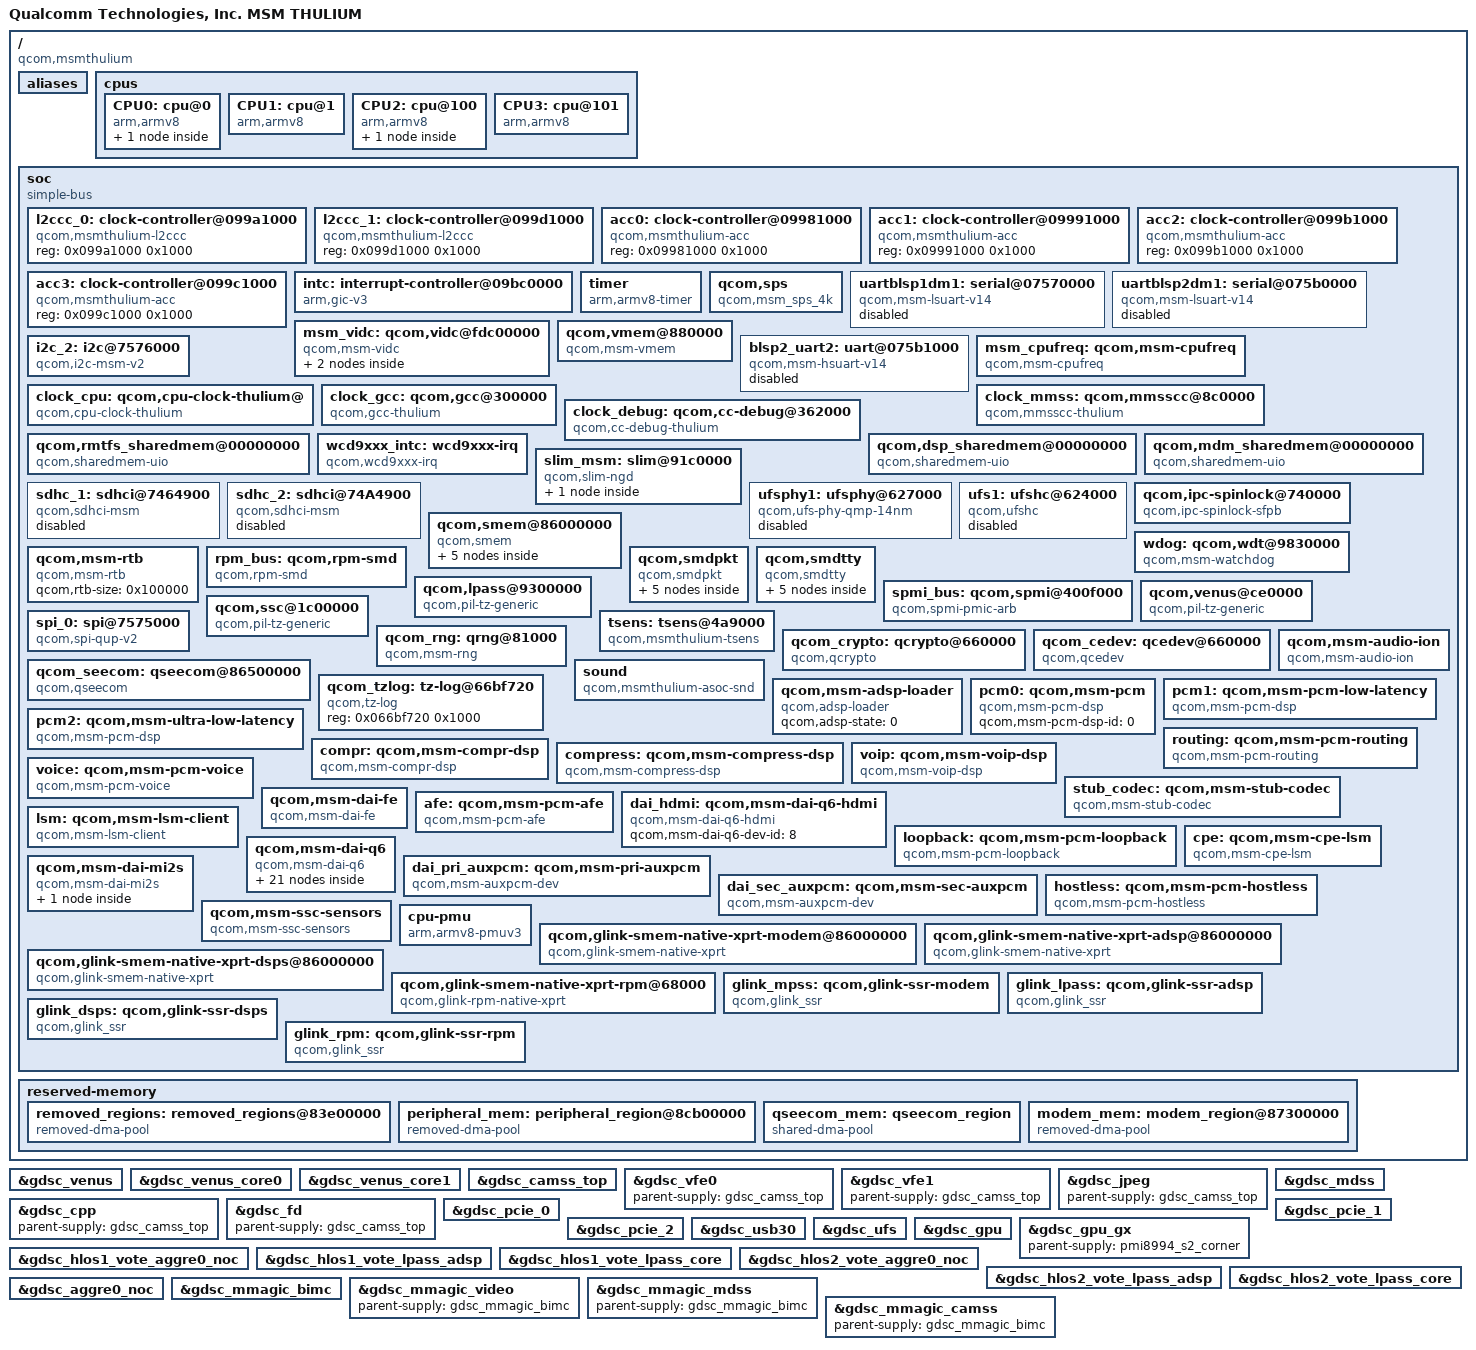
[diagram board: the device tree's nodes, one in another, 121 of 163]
/* Copyright (c) 2014-2015, The Linux Foundation. All rights reserved.
 *
 * This program is free software; you can redistribute it and/or modify
 * it under the terms of the GNU General Public License version 2 and
 * only version 2 as published by the Free Software Foundation.
 *
 * This program is distributed in the hope that it will be useful,
 * but WITHOUT ANY WARRANTY; without even the implied warranty of
 * MERCHANTABILITY or FITNESS FOR A PARTICULAR PURPOSE.  See the
 * GNU General Public License for more details.
 */

#include "skeleton64.dtsi"
#include <dt-bindings/clock/msm-clocks-thulium.h>

/ {
	model = "Qualcomm Technologies, Inc. MSM THULIUM";
	compatible = "qcom,msmthulium";
	qcom,msm-id = <246 0x0>;
	interrupt-parent = <&intc>;

	aliases {
		sdhc1 = &sdhc_1; /* SDC1 eMMC slot */
		sdhc2 = &sdhc_2; /* SDC2 SD card slot */
		smd7 = &smdtty_data1;
		smd8 = &smdtty_data4;
		smd11 = &smdtty_data11;
		smd21 = &smdtty_data21;
		smd36 = &smdtty_loopback;
		i2c2 = &i2c_2;
		spi0 = &spi_0;
	};

	cpus {
		#address-cells = <2>;
		#size-cells = <0>;

		CPU0: cpu@0 {
			device_type = "cpu";
			compatible = "arm,armv8";
			reg = <0x0 0x0>;
			enable-method = "qcom,msmthulium-acc";
			qcom,acc = <&acc0>;
			next-level-cache = <&L2_0>;
			L2_0: l2-cache {
			      compatible = "arm,arch-cache";
			      cache-level = <2>;
			      power-domain = <&l2ccc_0>;
			};

		};

		CPU1: cpu@1 {
			device_type = "cpu";
			compatible = "arm,armv8";
			reg = <0x0 0x1>;
			enable-method = "qcom,msmthulium-acc";
			qcom,acc = <&acc1>;
			next-level-cache = <&L2_0>;
		};

		CPU2: cpu@100 {
			device_type = "cpu";
			compatible = "arm,armv8";
			reg = <0x0 0x100>;
			enable-method = "qcom,msmthulium-acc";
			qcom,acc = <&acc2>;
			next-level-cache = <&L2_1>;
			L2_1: l2-cache {
			      compatible = "arm,arch-cache";
			      cache-level = <2>;
			      power-domain = <&l2ccc_1>;
			};
		};

		CPU3: cpu@101 {
			device_type = "cpu";
			compatible = "arm,armv8";
			reg = <0x0 0x101>;
			enable-method = "qcom,msmthulium-acc";
			qcom,acc = <&acc3>;
			next-level-cache = <&L2_1>;
		};

	};

	soc: soc { };

	reserved-memory {
		#address-cells = <2>;
		#size-cells = <2>;
		ranges;

		removed_regions: removed_regions@83e00000 {
			compatible = "removed-dma-pool";
			no-map;
			reg = <0 0x83e00000 0 0x3500000>;
		};

		peripheral_mem: peripheral_region@8cb00000 {
			compatible = "removed-dma-pool";
			no-map;
			reg = <0 0x8cb00000 0 0x2100000>;
		};

		qseecom_mem: qseecom_region {
			compatible = "shared-dma-pool";
			reusable;
			alignment = <0 0x400000>;
			size = <0 0x1400000>;
		};

		modem_mem: modem_region@87300000 {
			compatible = "removed-dma-pool";
			no-map;
			reg = <0 0x87300000 0 0x5800000>;
		};
	};
};

#include "msmthulium-ion.dtsi"
#include "msmthulium-mdss.dtsi"
#include "msmthulium-smp2p.dtsi"
#include "msmthulium-ipcrouter.dtsi"
#include "msmthulium-iommu.dtsi"
#include "msm-gdsc-thulium.dtsi"
#include "msmthulium-bus.dtsi"
#include "msmthulium-coresight.dtsi"

&soc {
	#address-cells = <1>;
	#size-cells = <1>;
	ranges = <0 0 0 0xffffffff>;
	compatible = "simple-bus";

	l2ccc_0: clock-controller@099a1000 {
		compatible = "qcom,msmthulium-l2ccc";
		reg = <0x099a1000 0x1000>;
	};

	l2ccc_1: clock-controller@099d1000 {
		compatible = "qcom,msmthulium-l2ccc";
		reg = <0x099d1000 0x1000>;
	};

	acc0: clock-controller@09981000 {
		compatible = "qcom,msmthulium-acc";
		reg = <0x09981000 0x1000>;
	};

	acc1: clock-controller@09991000 {
		compatible = "qcom,msmthulium-acc";
		reg = <0x09991000 0x1000>;
	};

	acc2: clock-controller@099b1000 {
		compatible = "qcom,msmthulium-acc";
		reg = <0x099b1000 0x1000>;
	};

	acc3: clock-controller@099c1000 {
		compatible = "qcom,msmthulium-acc";
		reg = <0x099c1000 0x1000>;
	};

	intc: interrupt-controller@09bc0000 {
		compatible = "arm,gic-v3";
		#interrupt-cells = <3>;
		interrupt-controller;
		#redistributor-regions = <1>;
		redistributor-stride = <0x0 0x40000>;
		reg = <0x09bc0000 0x10000>,       /* GICD */
		      <0x09c00000 0x100000>;      /* GICR * 4 */
		interrupts = <1 9 4>;
	};

	timer {
		compatible = "arm,armv8-timer";
		interrupts = <1 13 0xf08>,
			     <1 14 0xf08>,
			     <1 11 0xf08>,
			     <1 10 0xf08>;
		clock-frequency = <19200000>;
	};

	qcom,sps {
		compatible = "qcom,msm_sps_4k";
		qcom,device-type = <3>;
		qcom,pipe-attr-ee;
	};

	uartblsp1dm1: serial@07570000 {
		compatible = "qcom,msm-lsuart-v14";
		reg = <0x7570000 0x1000>;
		interrupts = <0 108 0>;
		status = "disabled";
		clocks = <&clock_gcc clk_gcc_blsp1_uart2_apps_clk>,
			 <&clock_gcc clk_gcc_blsp1_ahb_clk>;
		clock-names = "core_clk", "iface_clk";
	};

	uartblsp2dm1: serial@075b0000 {
		compatible = "qcom,msm-lsuart-v14";
		reg = <0x75b0000 0x1000>;
		interrupts = <0 114 0>;
		status = "disabled";
		clocks = <&clock_gcc clk_gcc_blsp2_uart2_apps_clk>,
			 <&clock_gcc clk_gcc_blsp2_ahb_clk>;
		clock-names = "core_clk", "iface_clk";
	};

	msm_vidc: qcom,vidc@fdc00000 {
		compatible = "qcom,msm-vidc";
		status = "ok";
		reg = <0xC00000 0xff000>;
		interrupts = <0 287 0>;
		qcom,hfi = "venus";
		qcom,max-hw-load = <1281600>; /* Full 4k @ 30 + 1080p @ 30 */
		qcom,imem-size = <1048576>; /* 1 MB */
		qcom,load-freq-tbl =
			/* Encoders */
			<972000 450000000 0x55555555>, /* 4k UHD @ 30 */
			<489600 320000000 0x55555555>, /* 1080p @ 60 */
			<216000 150000000 0x55555555>, /* 720p @ 60 */
			<108000  75000000 0x55555555>, /* 720p @ 30 */

			/* Decoders */
			<1944000 450000000 0xffffffff>, /* 4k UHD @ 60 */
			< 972000 320000000 0xffffffff>, /* 4k UHD @ 30 */
			< 489600 150000000 0xffffffff>, /* 1080p @ 60 */
			< 244800  75000000 0xffffffff>; /* 1080p @ 30 */

		/* Regulators */
		/* Note: don't change the order of the regulators below as they
		 * correspond to the order in which the driver enables them.
		 */
		mmagic-venus-supply = <&gdsc_mmagic_video>;
		venus-supply = <&gdsc_venus>;
		venus-core0-supply = <&gdsc_venus_core0>;
		venus-core1-supply = <&gdsc_venus_core1>;

		/* Clocks */
		clock-names = "smmu_ahb_clk", "smmu_axi_clk", "core_clk", "iface_clk",
			"bus_clk", "maxi_clk", "core0_clk", "core1_clk";
		clocks = <&clock_mmss clk_smmu_video_ahb_clk>,
		       <&clock_mmss clk_smmu_video_axi_clk>,
		       <&clock_mmss clk_video_core_clk>,
		       <&clock_mmss clk_video_ahb_clk>,
		       <&clock_mmss clk_video_axi_clk>,
		       <&clock_mmss clk_video_maxi_clk>,
		       <&clock_mmss clk_video_subcore0_clk>,
		       <&clock_mmss clk_video_subcore1_clk>;
		qcom,clock-configs = <0x0 0x0 0x1 0x0 0x0 0x0 0x1 0x1>;

		/* MMUs */
		non_secure_cb {
			compatible = "qcom,msm-vidc,context-bank";
			label = "venus_ns";
			iommus = <&venus_smmu 0x00>,
				<&venus_smmu 0x01>,
				<&venus_smmu 0x0a>,
				<&venus_smmu 0x07>,
				<&venus_smmu 0x0e>,
				<&venus_smmu 0x0f>,
				<&venus_smmu 0x08>,
				<&venus_smmu 0x09>,
				<&venus_smmu 0x0b>,
				<&venus_smmu 0x0c>,
				<&venus_smmu 0x0d>,
				<&venus_smmu 0x10>,
				<&venus_smmu 0x11>,
				<&venus_smmu 0x21>,
				<&venus_smmu 0x28>,
				<&venus_smmu 0x29>,
				<&venus_smmu 0x2b>,
				<&venus_smmu 0x2c>,
				<&venus_smmu 0x2d>,
				<&venus_smmu 0x31>;
			buffer-types = <0xfff>;
			virtual-addr-pool = <0x5dc00000 0x80000000>;
		};
		firmware_cb {
			compatible = "qcom,msm-vidc,context-bank";
			qcom,fw-context-bank;
			iommus = <&venus_smmu 0x180>,
				<&venus_smmu 0x186>;
		};
	};

	qcom,vmem@880000 {
		compatible = "qcom,msm-vmem";
		interrupts = <0 429 0>;
		reg = <0x880000 0x800>,
		    <0x6800000 0x100000>;
		reg-names = "reg-base", "mem-base";

		clocks = <&clock_mmss clk_vmem_ahb_clk>,
		       <&clock_mmss clk_vmem_maxi_clk>;
		clock-names = "ahb", "maxi";
		qcom,banks = <4>;
	};

	i2c_2: i2c@7576000 { /* BLSP1 QUP2 */
		compatible = "qcom,i2c-msm-v2";
		#address-cells = <1>;
		#size-cells = <0>;
		reg-names = "qup_phys_addr", "bam_phys_addr";
		reg = <0x7576000 0x1000>,
		      <0x7544000 0x19000>;
		interrupt-names = "qup_irq", "bam_irq";
		interrupts = <0 96 0>, <0 238 0>;
		qcom,clk-freq-out = <100000>;
		qcom,clk-freq-in  = <19200000>;
		clock-names = "iface_clk", "core_clk";
		clocks = <&clock_gcc clk_gcc_blsp1_ahb_clk>,
			 <&clock_gcc clk_gcc_blsp1_qup2_i2c_apps_clk>;

		pinctrl-names = "i2c_active", "i2c_sleep";
		pinctrl-0 = <&i2c_2_active>;
		pinctrl-1 = <&i2c_2_sleep>;
		qcom,noise-rjct-scl = <0>;
		qcom,noise-rjct-sda = <0>;
		qcom,bam-pipe-idx-cons = <14>;
		qcom,bam-pipe-idx-prod = <15>;
		qcom,master-id = <86>;
	};

	blsp2_uart2: uart@075b1000 { /* BLSP2 UART2 */
		compatible = "qcom,msm-hsuart-v14";
		reg = <0x075b1000 0x1000>,
		    <0x7584000 0x12b000>;
		status = "disabled";
		reg-names = "core_mem", "bam_mem";
		interrupt-names = "core_irq", "bam_irq", "wakeup_irq";
		#address-cells = <0>;
		interrupt-parent = <&blsp2_uart2>;
		interrupts = <0 1 2>;
		#interrupt-cells = <1>;
		interrupt-map-mask = <0xffffffff>;
		interrupt-map = <0 &intc 0 114 0
			    1 &intc 0 239 0
			    2 &tlmm 5 0>;

		qcom,inject-rx-on-wakeup;
		qcom,rx-char-to-inject = <0xFD>;

		qcom,bam-tx-ep-pipe-index = <2>;
		qcom,bam-rx-ep-pipe-index = <3>;
		qcom,master-id = <84>;
		clock-names = "core_clk", "iface_clk";
		clocks = <&clock_gcc clk_gcc_blsp2_uart2_apps_clk>,
		    <&clock_gcc clk_gcc_blsp2_ahb_clk>;
		pinctrl-names = "sleep", "default";
		pinctrl-0 = <&blsp2_uart2_sleep>;
		pinctrl-1 = <&blsp2_uart2_active>;

		qcom,msm-bus,name = "buart8";
		qcom,msm-bus,num-cases = <2>;
		qcom,msm-bus,num-paths = <1>;
		qcom,msm-bus,vectors-KBps =
			    <84 512 0 0>,
			    <84 512 500 800>;
	};

	msm_cpufreq: qcom,msm-cpufreq {
		compatible = "qcom,msm-cpufreq";
		clock-names = "l2_clk", "cpu0_clk", "cpu1_clk", "cpu2_clk",
				"cpu3_clk";
		clocks = <&clock_cpu clk_cbf_hf_mux>,
			 <&clock_cpu clk_pwrcl_clk>,
			 <&clock_cpu clk_pwrcl_clk>,
			 <&clock_cpu clk_perfcl_clk>,
			 <&clock_cpu clk_perfcl_clk>;

		qcom,governor-per-policy;

		qcom,cpufreq-table-0 =
			<  300000 >,
			<  345600 >,
			<  422400 >,
			<  499200 >,
			<  576000 >,
			<  652800 >,
			<  729600 >,
			<  806400 >,
			<  883200 >,
			<  960000 >,
			< 1036800 >,
			< 1113600 >,
			< 1190400 >,
			< 1267200 >,
			< 1344000 >,
			< 1420800 >,
			< 1459200 >;

		qcom,cpufreq-table-2 =
			<  300000 >,
			<  345600 >,
			<  422400 >,
			<  499200 >,
			<  576000 >,
			<  652800 >,
			<  729600 >,
			<  806400 >,
			<  883200 >,
			<  960000 >,
			< 1036800 >,
			< 1113600 >,
			< 1190400 >,
			< 1267200 >,
			< 1344000 >,
			< 1420800 >,
			< 1497600 >,
			< 1593600 >;
	};

	clock_cpu: qcom,cpu-clock-thulium@ {
		compatible = "qcom,cpu-clock-thulium";
		reg = <0x06400000 0x1000>,
		      <0x06480000 0x1000>,
		      <0x09A20000 0x1000>,
		      <0x06400000 0x1000>,
		      <0x06480000 0x1000>,
		      <0x09A11000 0x1000>,
		      <0x00070130 0x8>;
		reg-names = "pwrcl_pll", "perfcl_pll", "cbf_pll", "pwrcl_mux", "perfcl_mux", "cbf_mux", "efuse";
		vdd-pwrcl-supply = <&apc_vreg_corner>;
		vdd-perfcl-supply = <&apc_vreg_corner>;
		vdd-cbf-supply = <&apc_vreg_corner>;
		vdd-dig-supply = <&pm8994_s1_corner_ao>;
		qcom,pwrcl-speedbin0-v0 =
			<          0  0 >,
			<  300000000  1 >,
			<  345600000  2 >,
			<  422400000  3 >,
			<  499200000  4 >,
			<  576000000  5 >,
			<  652800000  6 >,
			<  729600000  7 >,
			<  806400000  8 >,
			<  883200000  9 >,
			<  960000000 10 >,
			< 1036800000 11 >,
			< 1113600000 12 >,
			< 1190400000 13 >,
			< 1267200000 14 >,
			< 1344000000 15 >,
			< 1420800000 16 >,
			< 1459200000 18 >;
		qcom,perfcl-speedbin0-v0 =
			<          0  0 >,
			<  300000000  1 >,
			<  345600000  2 >,
			<  422400000  3 >,
			<  499200000  4 >,
			<  576000000  5 >,
			<  652800000  6 >,
			<  729600000  7 >,
			<  806400000  8 >,
			<  883200000  9 >,
			<  960000000 10 >,
			< 1036800000 11 >,
			< 1113600000 12 >,
			< 1190400000 13 >,
			< 1267200000 14 >,
			< 1344000000 15 >,
			< 1420800000 16 >,
			< 1497600000 17 >,
			< 1593600000 18 >;
		qcom,cbf-speedbin0-v0 =
			<	   0  0 >,
			<  300000000  1 >,
			<  384000000  3 >,
			<  499200000  4 >,
			<  600000000  5 >,
			<  692120000  6 >,
			<  787200000  7 >,
			<  883200000  8 >,
			< 1036800000 18 >;
		clock-names = "xo_ao", "aux_clk";
		clocks = <&clock_gcc clk_cxo_clk_src_ao>,
			 <&clock_gcc clk_gpll0_ao>;
		#clock-cells = <1>;
	};

	clock_gcc: qcom,gcc@300000 {
		compatible = "qcom,gcc-thulium";
		reg = <0x300000 0x8f014>;
		reg-names = "cc_base";
		vdd_dig-supply = <&pm8994_s1_corner>;
		#clock-cells = <1>;
	};

	clock_mmss: qcom,mmsscc@8c0000 {
		compatible = "qcom,mmsscc-thulium";
		reg = <0x8c0000 0xb00c>;
		reg-names = "cc_base";
		vdd_dig-supply = <&pm8994_s1_corner>;
		mmpll4_dig-supply = <&pm8994_s1_corner>;
		mmpll4_analog-supply = <&pm8994_l12>;
		clock-names = "xo", "gpll0";
		clocks = <&clock_gcc clk_cxo_clk_src>,
			 <&clock_gcc clk_gpll0_out_main>;
		#clock-cells = <1>;
	};

	clock_debug: qcom,cc-debug@362000 {
		compatible = "qcom,cc-debug-thulium";
		reg = <0x362000 0x4>;
		reg-names = "cc_base";
		clock-names = "debug_mmss_clk";
		clocks = <&clock_mmss clk_mmss_gcc_dbg_clk>;
		#clock-cells = <1>;
	};

	qcom,rmtfs_sharedmem@00000000 {
		compatible = "qcom,sharedmem-uio";
		reg = <0x00000000 0x00180000>;
		reg-names = "rmtfs";
		qcom,client-id = <0x00000001>;
	};

	qcom,dsp_sharedmem@00000000 {
		compatible = "qcom,sharedmem-uio";
		reg = <0x00000000 0x00010000>;
		reg-names = "rfsa_dsp";
		qcom,client-id = <0x011013ec>;
	};

	qcom,mdm_sharedmem@00000000 {
		compatible = "qcom,sharedmem-uio";
		reg = <0x00000000 0x00010000>;
		reg-names = "rfsa_mdm";
		qcom,client-id = <0x011013ed>;
	};

	wcd9xxx_intc: wcd9xxx-irq {
		compatible = "qcom,wcd9xxx-irq";
		interrupt-controller;
		#interrupt-cells = <1>;
		interrupt-parent = <&tlmm>;
		interrupts = <54 0>;
		interrupt-names = "cdc-int";
	};

	slim_msm: slim@91c0000 {
		cell-index = <1>;
		compatible = "qcom,slim-ngd";
		reg = <0x91c0000 0x2C000>,
			<0x9184000 0x32000>;
		reg-names = "slimbus_physical", "slimbus_bam_physical";
		interrupts = <0 163 0>, <0 164 0>;
		interrupt-names = "slimbus_irq", "slimbus_bam_irq";
		qcom,apps-ch-pipes = <0x60000000>;
		qcom,ea-pc = <0x160>;

		tomtom_codec {
			compatible = "qcom,tomtom-slim-pgd";
			elemental-addr = [00 01 30 01 17 02];

			interrupt-parent = <&wcd9xxx_intc>;
			interrupts = <0 1 2 3 4 5 6 7 8 9 10 11 12 13 14 15 16
				      17 18 19 20 21 22 23 24 25 26 27 28 29
				      30 31>;

			qcom,cdc-reset-gpio = <&tlmm 64 0>;

			cdc-vdd-buck-supply = <&pm8994_s5>;
			qcom,cdc-vdd-buck-voltage = <2150000 2150000>;
			qcom,cdc-vdd-buck-current = <650000>;

			cdc-vdd-tx-h-supply = <&pm8994_s4>;
			qcom,cdc-vdd-tx-h-voltage = <1800000 1800000>;
			qcom,cdc-vdd-tx-h-current = <25000>;

			cdc-vdd-rx-h-supply = <&pm8994_s4>;
			qcom,cdc-vdd-rx-h-voltage = <1800000 1800000>;
			qcom,cdc-vdd-rx-h-current = <25000>;

			cdc-vddpx-1-supply = <&pm8994_s4>;
			qcom,cdc-vddpx-1-voltage = <1800000 1800000>;
			qcom,cdc-vddpx-1-current = <10000>;

			cdc-vdd-a-1p2v-supply = <&pm8994_l11>;
			qcom,cdc-vdd-a-1p2v-voltage = <1200000 1200000>;
			qcom,cdc-vdd-a-1p2v-current = <2000>;

			cdc-vddcx-1-supply = <&pm8994_l11>;
			qcom,cdc-vddcx-1-voltage = <1200000 1200000>;
			qcom,cdc-vddcx-1-current = <33000>;

			cdc-vddcx-2-supply = <&pm8994_l11>;
			qcom,cdc-vddcx-2-voltage = <1200000 1200000>;
			qcom,cdc-vddcx-2-current = <33000>;

			qcom,cdc-static-supplies = "cdc-vdd-buck",
						   "cdc-vdd-tx-h",
						   "cdc-vdd-rx-h",
						   "cdc-vddpx-1",
						   "cdc-vdd-a-1p2v",
						   "cdc-vddcx-1",
						   "cdc-vddcx-2";

			qcom,cdc-micbias-ldoh-v = <0x3>;
			qcom,cdc-micbias-cfilt1-mv = <1800>;
			qcom,cdc-micbias-cfilt2-mv = <2700>;
			qcom,cdc-micbias-cfilt3-mv = <1800>;
			qcom,cdc-micbias1-cfilt-sel = <0x0>;
			qcom,cdc-micbias2-cfilt-sel = <0x1>;
			qcom,cdc-micbias3-cfilt-sel = <0x2>;
			qcom,cdc-micbias4-cfilt-sel = <0x2>;
			qcom,cdc-mclk-clk-rate = <9600000>;
			qcom,cdc-slim-ifd = "tomtom-slim-ifd";
			qcom,cdc-slim-ifd-elemental-addr = [00 00 30 01 17 02];
			qcom,cdc-dmic-sample-rate = <4800000>;
			qcom,cdc-mad-dmic-rate = <600000>;
			qcom,cdc-variant = "WCD9330";
		};
	};

	sdhc_1: sdhci@7464900 {
		compatible = "qcom,sdhci-msm";
		reg = <0x7464900 0x314>, <0x7464000 0x800>, <0x7464E00 0x19C>;
		reg-names = "hc_mem", "core_mem", "cmdq_mem";

		interrupts = <0 141 0>, <0 134 0>;
		interrupt-names = "hc_irq", "pwr_irq";

		clock-names = "iface_clk", "core_clk";
		clocks = <&clock_gcc clk_gcc_sdcc1_ahb_clk>,
			 <&clock_gcc clk_gcc_sdcc1_apps_clk>;

		qcom,bus-width = <8>;
		qcom,cpu-dma-latency-us = <701>;

		qcom,msm-bus,name = "sdhc1";
		qcom,msm-bus,num-cases = <9>;
		qcom,msm-bus,num-paths = <1>;
		qcom,msm-bus,vectors-KBps = <78 512 0 0>, /* No vote */
			<78 512 1600 3200>,       /* 400 KB/s*/
			<78 512 80000 160000>,    /* 20 MB/s */
			<78 512 100000 200000>,   /* 25 MB/s */
			<78 512 200000 400000>,   /* 50 MB/s */
			<78 512 400000 800000>,   /* 100 MB/s */
			<78 512 400000 800000>,   /* 200 MB/s */
			<78 512 400000 800000>,   /* 400 MB/s */
			<78 512 2048000 4096000>; /* Max. bandwidth */
		qcom,bus-bw-vectors-bps = <0 400000 20000000 25000000 50000000
						100000000 200000000 400000000
						4294967295>;

		status = "disabled";
	};

	sdhc_2: sdhci@74A4900 {
		compatible = "qcom,sdhci-msm";
		reg = <0x74A4900 0x314>, <0x74A4000 0x800>;
		reg-names = "hc_mem", "core_mem";

		interrupts = <0 125 0>, <0 221 0>;
		interrupt-names = "hc_irq", "pwr_irq";

		clock-names = "iface_clk", "core_clk";
		clocks = <&clock_gcc clk_gcc_sdcc2_ahb_clk>,
			 <&clock_gcc clk_gcc_sdcc2_apps_clk>;

		qcom,bus-width = <4>;
		qcom,cpu-dma-latency-us = <701>;

		qcom,msm-bus,name = "sdhc2";
		qcom,msm-bus,num-cases = <8>;
		qcom,msm-bus,num-paths = <1>;
		qcom,msm-bus,vectors-KBps = <81 512 0 0>, /* No vote */
				<81 512 1600 3200>,    /* 400 KB/s*/
				<81 512 80000 160000>, /* 20 MB/s */
				<81 512 100000 200000>, /* 25 MB/s */
				<81 512 200000 400000>, /* 50 MB/s */
				<81 512 400000 800000>, /* 100 MB/s */
				<81 512 800000 800000>, /* 200 MB/s */
				<81 512 2048000 4096000>; /* Max. bandwidth */
		qcom,bus-bw-vectors-bps = <0 400000 20000000 25000000 50000000
						100000000 200000000 4294967295>;

		status = "disabled";
	};

	ufsphy1: ufsphy@627000 {
		compatible = "qcom,ufs-phy-qmp-14nm";
		reg = <0x627000 0xda8>;
		reg-names = "phy_mem";
		#phy-cells = <0>;
		vdda-phy-supply = <&pm8994_l28>;
		vdda-pll-supply = <&pm8994_l12>;
		vdda-phy-max-microamp = <45000>;
		vdda-pll-max-microamp = <100>;
		vddp-ref-clk-supply = <&pm8994_l25>;
		vddp-ref-clk-max-microamp = <100>;
		vddp-ref-clk-always-on;
		clock-names = "ref_clk_src",
			"ref_clk",
			"tx_iface_clk",
			"rx_iface_clk";
		clocks = <&clock_gcc clk_ln_bb_clk>,
			<&clock_gcc clk_gcc_ufs_clkref_clk>,
			<&clock_gcc clk_gcc_ufs_tx_cfg_clk>,
			<&clock_gcc clk_gcc_ufs_rx_cfg_clk>;
		status = "disabled";
	};

	ufs1: ufshc@624000 {
		compatible = "qcom,ufshc";
		reg = <0x624000 0x2500>;
		interrupts = <0 265 0>;
		phys = <&ufsphy1>;
		phy-names = "ufsphy";
		vdd-hba-supply = <&gdsc_ufs>;
		vdd-hba-fixed-regulator;
		vcc-supply = <&pm8994_l20>;
		vccq-supply = <&pm8994_l25>;
		vccq2-supply = <&pm8994_s4>;
		vcc-max-microamp = <750000>;
		vccq-max-microamp = <50000>;
		vccq2-max-microamp = <750000>;

		clock-names =
			"core_clk_src",
			"core_clk",
			"bus_clk",
			"iface_clk",
			"ref_clk",
			"tx_lane0_sync_clk",
			"rx_lane0_sync_clk";
		clocks =
			<&clock_gcc clk_ufs_axi_clk_src>,
			<&clock_gcc clk_gcc_ufs_axi_clk>,
			<&clock_gcc clk_gcc_sys_noc_ufs_axi_clk>,
			<&clock_gcc clk_gcc_ufs_ahb_clk>,
			<&clock_gcc clk_bb_clk1>,
			<&clock_gcc clk_gcc_ufs_tx_symbol_0_clk>,
			<&clock_gcc clk_gcc_ufs_rx_symbol_1_clk>;

		lanes-per-direction = <1>;
		qcom,msm-bus,name = "ufs1";
		qcom,msm-bus,num-cases = <12>;
		qcom,msm-bus,num-paths = <2>;
		qcom,msm-bus,vectors-KBps =
		<95 512 0 0>, <1 650 0 0>,          /* No vote */
		<95 512 922 0>, <1 650 1000 0>,     /* PWM G1 */
		<95 512 1844 0>, <1 650 1000 0>,    /* PWM G2 */
		<95 512 3688 0>, <1 650 1000 0>,    /* PWM G3 */
		<95 512 7376 0>, <1 650 1000 0>,    /* PWM G4 */
		<95 512 127796 0>, <1 650 1000 0>,  /* HS G1 RA */
		<95 512 255591 0>, <1 650 1000 0>,  /* HS G2 RA */
		<95 512 511181 0>, <1 650 1000 0>,  /* HS G3 RA */
		<95 512 149422 0>, <1 650 1000 0>,  /* HS G1 RB */
		<95 512 298189 0>, <1 650 1000 0>,  /* HS G2 RB */
		<95 512 596378 0>, <1 650 1000 0>,  /* HS G3 RB */
		<95 512 4096000 0>, <1 650 1000 0>; /* Max. bandwidth */
		qcom,bus-vector-names = "MIN",
		"PWM_G1_L1", "PWM_G2_L1", "PWM_G3_L1", "PWM_G4_L1",
		"HS_RA_G1_L1", "HS_RA_G2_L1", "HS_RA_G3_L1",
		"HS_RB_G1_L1", "HS_RB_G2_L1", "HS_RB_G3_L1",
		"MAX";

		spm-level = <5>;

		qcom,cpu-affinity = "affine_cores";
		qcom,cpu-dma-latency-us = <301>;

		status = "disabled";
	};

        qcom,ipc-spinlock@740000 {
                compatible = "qcom,ipc-spinlock-sfpb";
                reg = <0x740000 0x8000>;
                qcom,num-locks = <8>;
        };

	qcom,smem@86000000 {
		compatible = "qcom,smem";
		reg = <0x86000000 0x200000>,
			<0x9820010 0x4>,
			<0x68000 0x8000>,
			<0x7b4000 0x8>;
		reg-names = "smem", "irq-reg-base", "aux-mem1",
			"smem_targ_info_reg";
		qcom,mpu-enabled;

		qcom,smd-modem {
			compatible = "qcom,smd";
			qcom,smd-edge = <0>;
			qcom,smd-irq-offset = <0x0>;
			qcom,smd-irq-bitmask = <0x1000>;
			interrupts = <0 25 1>;
			label = "modem";
		};

		qcom,smsm-modem {
			compatible = "qcom,smsm";
			qcom,smsm-edge = <0>;
			qcom,smsm-irq-offset = <0x0>;
			qcom,smsm-irq-bitmask = <0x2000>;
			interrupts = <0 26 1>;
		};

		qcom,smd-adsp {
			compatible = "qcom,smd";
			qcom,smd-edge = <1>;
			qcom,smd-irq-offset = <0x0>;
			qcom,smd-irq-bitmask = <0x100>;
			interrupts = <0 156 1>;
			label = "adsp";
		};

		qcom,smd-dsps {
			compatible = "qcom,smd";
			qcom,smd-edge = <3>;
			qcom,smd-irq-offset = <0x0>;
			qcom,smd-irq-bitmask = <0x1000000>;
			interrupts = <0 176 1>;
			label = "dsps";
		};

		qcom,smd-rpm {
			compatible = "qcom,smd";
			qcom,smd-edge = <15>;
			qcom,smd-irq-offset = <0x0>;
			qcom,smd-irq-bitmask = <0x1>;
			interrupts = <0 168 1>;
			label = "rpm";
			qcom,irq-no-suspend;
			qcom,not-loadable;
		};
	};

	wdog: qcom,wdt@9830000 {
		compatible = "qcom,msm-watchdog";
		reg = <0x9830000 0x1000>;
		reg-names = "wdt-base";
		interrupts = <0 28 0>, <0 29 0>;
		qcom,bark-time = <11000>;
		qcom,pet-time = <10000>;
		qcom,ipi-ping;
	};

	qcom,msm-rtb {
		compatible = "qcom,msm-rtb";
		qcom,rtb-size = <0x100000>;
	};

	rpm_bus: qcom,rpm-smd {
		 compatible = "qcom,rpm-smd";
		 rpm-channel-name = "rpm_requests";
		 rpm-channel-type = <15>;
	 };

	qcom,smdpkt {
		compatible = "qcom,smdpkt";

		qcom,smdpkt-data5-cntl {
			qcom,smdpkt-remote = "modem";
			qcom,smdpkt-port-name = "DATA5_CNTL";
			qcom,smdpkt-dev-name = "smdcntl0";
		};

		qcom,smdpkt-data22 {
			qcom,smdpkt-remote = "modem";
			qcom,smdpkt-port-name = "DATA22";
			qcom,smdpkt-dev-name = "smd22";
		};

		qcom,smdpkt-data40-cntl {
			qcom,smdpkt-remote = "modem";
			qcom,smdpkt-port-name = "DATA40_CNTL";
			qcom,smdpkt-dev-name = "smdcntl8";
		};

		qcom,smdpkt-apr-apps2 {
			qcom,smdpkt-remote = "modem";
			qcom,smdpkt-port-name = "apr_apps2";
			qcom,smdpkt-dev-name = "apr_apps2";
		};

		qcom,smdpkt-loopback {
			qcom,smdpkt-remote = "modem";
			qcom,smdpkt-port-name = "LOOPBACK";
			qcom,smdpkt-dev-name = "smd_pkt_loopback";
		};
	};

	qcom,smdtty {
		compatible = "qcom,smdtty";

		smdtty_data1: qcom,smdtty-data1 {
			qcom,smdtty-remote = "modem";
			qcom,smdtty-port-name = "DATA1";
		};

		smdtty_data4: qcom,smdtty-data4 {
			qcom,smdtty-remote = "modem";
			qcom,smdtty-port-name = "DATA4";
		};

		smdtty_data11: qcom,smdtty-data11 {
			qcom,smdtty-remote = "modem";
			qcom,smdtty-port-name = "DATA11";
		};

		smdtty_data21: qcom,smdtty-data21 {
			qcom,smdtty-remote = "modem";
			qcom,smdtty-port-name = "DATA21";
		};

		smdtty_loopback: smdtty-loopback {
			qcom,smdtty-remote = "modem";
			qcom,smdtty-port-name = "LOOPBACK";
			qcom,smdtty-dev-name = "LOOPBACK_TTY";
		};
	};

	spmi_bus: qcom,spmi@400f000 {
		compatible = "qcom,spmi-pmic-arb";
		reg = <0x400f000 0x1000>,
			<0x4400000 0x800000>,
			<0x4c00000 0x800000>,
			<0x5800000 0x200000>,
			<0x400a000 0x2100>; /* includes SPMI_CFG and GENI_CFG */
		reg-names = "core", "chnls", "obsrvr", "intr", "cnfg";
		interrupts = <0 326 0>;
		qcom,pmic-arb-channel = <0>;
		qcom,pmic-arb-ee = <0>;
		#interrupt-cells = <3>;
		interrupt-controller;
		#address-cells = <1>;
		#size-cells = <0>;
		cell-index = <0>;
		qcom,not-wakeup; /* Required until RPM is fully configured. */
	};

	qcom,lpass@9300000 {
		compatible = "qcom,pil-tz-generic";
		reg = <0x9300000 0x00100>;
		interrupts = <0 162 1>;

		vdd_cx-supply = <&pm8994_s1_corner>;
		qcom,proxy-reg-names = "vdd_cx";
		qcom,vdd_cx-uV-uA = <7 100000>;

		clocks = <&clock_gcc clk_cxo_pil_lpass_clk>;
		clock-names = "xo";
		qcom,proxy-clock-names = "xo";

		qcom,pas-id = <1>;
		qcom,proxy-timeout-ms = <10000>;
		qcom,smem-id = <423>;
		qcom,sysmon-id = <1>;
		qcom,ssctl-instance-id = <0x14>;
		qcom,firmware-name = "adsp";
		memory-region = <&peripheral_mem>;
	};

	qcom,venus@ce0000 {
		compatible = "qcom,pil-tz-generic";
		reg = <0xce0000 0x4000>;

		vdd-supply = <&gdsc_venus>;
		qcom,proxy-reg-names = "vdd";

		clocks = <&clock_mmss clk_video_core_clk>,
			<&clock_mmss clk_video_ahb_clk>,
			<&clock_mmss clk_video_axi_clk>,
			<&clock_mmss clk_video_maxi_clk>,
			<&clock_mmss clk_vmem_maxi_clk>;
		clock-names = "core_clk", "iface_clk",
				"bus_clk", "maxi_clk", "vmem_maxi";
		qcom,proxy-clock-names = "core_clk", "iface_clk",
				"bus_clk", "maxi_clk", "vmem_maxi";

		qcom,msm-bus,name = "pil-venus";
		qcom,msm-bus,num-cases = <2>;
		qcom,msm-bus,num-paths = <1>;
		qcom,msm-bus,vectors-KBps =
				<63 512 0 0>,
				<63 512 0 304000>;
		qcom,pas-id = <9>;
		qcom,proxy-timeout-ms = <5000>;
		qcom,firmware-name = "venus";
		memory-region = <&peripheral_mem>;
		qcom,pil-no-auth;
	};

	qcom,ssc@1c00000 {
		compatible = "qcom,pil-tz-generic";
		reg = <0x1c00000 0x4000>;
		interrupts = <0 390 1>;

		/* These may have to move to proxy votes in the future */
		vdd_cx-supply = <&pm8994_l26>;
		vdd_mx-supply = <&pm8994_l31>;
		vdd_px-supply = <&pm8994_lvs2>;
		qcom,vdd_cx-uV-uA = <645000 0>;
		qcom,vdd_mx-uV-uA = <765000 0>;
		qcom,active-reg-names = "vdd_cx", "vdd_mx", "vdd_px";

		clocks = <&clock_gcc clk_cxo_pil_ssc_clk>;
		clock-names = "xo";
		qcom,proxy-clock-names = "xo";

		qcom,pas-id = <12>;
		qcom,proxy-timeout-ms = <10000>;
		qcom,smem-id = <424>;
		qcom,sysmon-id = <3>;
		qcom,ssctl-instance-id = <0x16>;
		qcom,firmware-name = "slpi";
		memory-region = <&peripheral_mem>;
	};

	tsens: tsens@4a9000 {
		compatible = "qcom,msmthulium-tsens";
		reg = <0x4a8000 0x2000>,
			<0x74230 0x1000>;
		reg-names = "tsens_physical", "tsens_eeprom_physical";
		interrupts = <0 184 0>, <0 430 0>;
		interrupt-names = "tsens-upper-lower", "tsens-critical";
		qcom,sensors = <16>;
		qcom,slope = <2901 2846 3200 3200 3200 3200 3200 3200 3200 3200 3200 3200 3200 3200 3200 3200>;
	};

	spi_0: spi@7575000 { /* BLSP1 QUP1 */
		compatible = "qcom,spi-qup-v2";
		#address-cells = <1>;
		#size-cells = <0>;
		reg-names = "spi_physical", "spi_bam_physical";
		reg = <0x07575000 0x600>,
		      <0x07544000 0x2b000>;
		interrupt-names = "spi_irq", "spi_bam_irq";
		interrupts = <0 95 0>, <0 238 0>;
		spi-max-frequency = <19200000>;

		qcom,infinite-mode = <0>;
		qcom,use-bam;
		qcom,ver-reg-exists;
		qcom,bam-consumer-pipe-index = <12>;
		qcom,bam-producer-pipe-index = <13>;
		qcom,master-id = <86>;
		qcom,use-pinctrl;
		pinctrl-names = "spi_default", "spi_sleep";
		pinctrl-0 = <&spi_0_active>;
		pinctrl-1 = <&spi_0_sleep>;

		clock-names = "iface_clk", "core_clk";

		clocks = <&clock_gcc clk_gcc_blsp1_ahb_clk>,
			 <&clock_gcc clk_gcc_blsp1_qup1_spi_apps_clk>;
	};

	qcom_rng: qrng@81000 {
		compatible = "qcom,msm-rng";
		reg = <0x81000 0x1000>;
		qcom,msm-rng-iface-clk;
		qcom,msm-bus,name = "msm-rng-noc";
		qcom,msm-bus,num-cases = <2>;
		qcom,msm-bus,num-paths = <1>;
		qcom,msm-bus,vectors-KBps =
				<1 618 0 0>,		/* No vote */
				<1 618 0 800>;		/* 100 MB/s */
		clocks = <&clock_gcc clk_gcc_prng_ahb_clk>;
		clock-names = "iface_clk";
	};

	qcom_crypto: qcrypto@660000 {
		compatible = "qcom,qcrypto";
		reg = <0x660000 0x20000>,
		      <0x644000 0x24000>;
		reg-names = "crypto-base","crypto-bam-base";
		interrupts = <0 207 0>;
		qcom,bam-pipe-pair = <2>;
		qcom,ce-hw-instance = <0>;
		qcom,ce-device = <0>;
		qcom,msm-bus,name = "qcrypto-noc";
		qcom,msm-bus,num-cases = <2>;
		qcom,msm-bus,num-paths = <1>;
		qcom,msm-bus,vectors-KBps =
				<55 512 0 0>,
				<55 512 3936000 393600>;
		clock-names = "core_clk_src", "core_clk",
				"iface_clk", "bus_clk";
		clocks = <&clock_gcc clk_ce1_clk>,
			 <&clock_gcc clk_qcrypto_ce1_clk>,
			 <&clock_gcc clk_gcc_ce1_ahb_m_clk>,
			 <&clock_gcc clk_gcc_ce1_axi_m_clk>;
		qcom,ce-opp-freq = <171430000>;
		qcom,use-sw-aes-cbc-ecb-ctr-algo;
		qcom,use-sw-aes-xts-algo;
		qcom,use-sw-aes-ccm-algo;
		qcom,use-sw-ahash-algo;
	};

	qcom_cedev: qcedev@660000 {
		compatible = "qcom,qcedev";
		reg = <0x660000 0x20000>,
		      <0x644000 0x24000>;
		reg-names = "crypto-base","crypto-bam-base";
		interrupts = <0 207 0>;
		qcom,bam-pipe-pair = <1>;
		qcom,ce-hw-instance = <0>;
		qcom,ce-device = <0>;
		qcom,msm-bus,name = "qcedev-noc";
		qcom,msm-bus,num-cases = <2>;
		qcom,msm-bus,num-paths = <1>;
		qcom,msm-bus,vectors-KBps =
				<55 512 0 0>,
				<55 512 3936000 393600>;
		clock-names = "core_clk_src", "core_clk",
				"iface_clk", "bus_clk";
		clocks = <&clock_gcc clk_ce1_clk>,
			 <&clock_gcc clk_qcedev_ce1_clk>,
			 <&clock_gcc clk_gcc_ce1_ahb_m_clk>,
			 <&clock_gcc clk_gcc_ce1_axi_m_clk>;
		qcom,ce-opp-freq = <171430000>;
	};

	qcom_seecom: qseecom@86500000 {
		compatible = "qcom,qseecom";
		reg = <0x86500000 0xd00000>;
		reg-names = "secapp-region";
		qcom,hlos-num-ce-hw-instances = <1>;
		qcom,hlos-ce-hw-instance = <0>;
		qcom,qsee-ce-hw-instance = <0>;
		qcom,no-clock-support;
		qcom,msm-bus,name = "qseecom-noc";
		qcom,msm-bus,num-cases = <4>;
		qcom,msm-bus,num-paths = <1>;
		qcom,msm-bus,vectors-KBps =
				<55 512 0 0>,
				<55 512 0 0>,
				<55 512 120000 1200000>,
				<55 512 393600 3936000>;
		clock-names = "core_clk_src", "core_clk",
				"iface_clk", "bus_clk";
		clocks = <&clock_gcc clk_ce1_clk>,
			 <&clock_gcc clk_qseecom_ce1_clk>,
			 <&clock_gcc clk_gcc_ce1_ahb_m_clk>,
			 <&clock_gcc clk_gcc_ce1_axi_m_clk>;
		qcom,ce-opp-freq = <171430000>;
	};

	qcom_tzlog: tz-log@66bf720 {
		compatible = "qcom,tz-log";
		reg = <0x066bf720 0x1000>;
	};

	sound {
		compatible = "qcom,msmthulium-asoc-snd";
		qcom,model = "msmthulium-tomtom-snd-card";

		qcom,audio-routing =
			"AIF4 VI", "MCLK",
			"RX_BIAS", "MCLK",
			"LDO_H", "MCLK",
			"AIF4 MAD", "MCLK",
			"AMIC1", "MIC BIAS1 Internal1",
			"MIC BIAS1 Internal1", "Handset Mic",
			"AMIC2", "MIC BIAS2 External",
			"MIC BIAS2 External", "Headset Mic",
			"AMIC3", "MIC BIAS2 External",
			"MIC BIAS2 External", "ANCRight Headset Mic",
			"AMIC4", "MIC BIAS2 External",
			"MIC BIAS2 External", "ANCLeft Headset Mic",
			"DMIC1", "MIC BIAS1 External",
			"MIC BIAS1 External", "Digital Mic1",
			"DMIC2", "MIC BIAS1 External",
			"MIC BIAS1 External", "Digital Mic2",
			"DMIC3", "MIC BIAS3 External",
			"MIC BIAS3 External", "Digital Mic3",
			"DMIC4", "MIC BIAS3 External",
			"MIC BIAS3 External", "Digital Mic4",
			"DMIC5", "MIC BIAS4 External",
			"MIC BIAS4 External", "Digital Mic5",
			"DMIC6", "MIC BIAS4 External",
			"MIC BIAS4 External", "Digital Mic6";

		qcom,tomtom-mclk-clk-freq = <9600000>;
		pinctrl-names = "mi2s-sleep",
				"mi2s-active",
				"auxpcm-sleep",
				"auxpcm-active";
		pinctrl-0 = <&tert_mi2s_sleep>, <&tert_mi2s_sd0_sleep>;
		pinctrl-1 = <&tert_mi2s_active>, <&tert_mi2s_sd0_active>;
		pinctrl-2 = <&pri_aux_pcm_sleep>, <&pri_aux_pcm_din_sleep>;
		pinctrl-3 = <&pri_aux_pcm_active>, <&pri_aux_pcm_din_active>;
		asoc-platform = <&pcm0>, <&pcm1>, <&pcm2>, <&voip>, <&voice>,
				<&loopback>, <&compress>, <&hostless>,
				<&afe>, <&lsm>, <&routing>, <&cpe>, <&compr>;
		asoc-platform-names = "msm-pcm-dsp.0", "msm-pcm-dsp.1", "msm-pcm-dsp.2",
				"msm-voip-dsp", "msm-pcm-voice", "msm-pcm-loopback",
				"msm-compress-dsp", "msm-pcm-hostless", "msm-pcm-afe",
				"msm-lsm-client", "msm-pcm-routing", "msm-cpe-lsm",
				"msm-compr-dsp";
		asoc-cpu = <&dai_pri_auxpcm>, <&dai_sec_auxpcm>, <&dai_hdmi>, <&dai_mi2s>,
				<&sb_0_rx>, <&sb_0_tx>, <&sb_1_rx>, <&sb_1_tx>,
				<&sb_2_rx>, <&sb_2_tx>, <&sb_3_rx>, <&sb_3_tx>,
				<&sb_4_rx>, <&sb_4_tx>, <&sb_5_tx>, <&afe_pcm_rx>,
				<&afe_pcm_tx>, <&afe_proxy_rx>, <&afe_proxy_tx>,
				<&incall_record_rx>, <&incall_record_tx>,
				<&incall_music_rx>, <&incall_music2_rx>;
		asoc-cpu-names = "msm-dai-q6-auxpcm.1", "msm-dai-q6-auxpcm.2",
				"msm-dai-q6-hdmi.8", "msm-dai-q6-mi2s.2",
				"msm-dai-q6-dev.16384", "msm-dai-q6-dev.16385",
				"msm-dai-q6-dev.16386", "msm-dai-q6-dev.16387",
				"msm-dai-q6-dev.16388", "msm-dai-q6-dev.16389",
				"msm-dai-q6-dev.16390", "msm-dai-q6-dev.16391",
				"msm-dai-q6-dev.16392", "msm-dai-q6-dev.16393",
				"msm-dai-q6-dev.16395", "msm-dai-q6-dev.224",
				"msm-dai-q6-dev.225", "msm-dai-q6-dev.241",
				"msm-dai-q6-dev.240", "msm-dai-q6-dev.32771",
				"msm-dai-q6-dev.32772", "msm-dai-q6-dev.32773",
				"msm-dai-q6-dev.32770";
		asoc-codec = <&stub_codec>;
		asoc-codec-names = "msm-stub-codec.1";
	};

	qcom,msm-adsp-loader {
		status = "ok";
		compatible = "qcom,adsp-loader";
		qcom,adsp-state = <0>;
	};

	qcom,msm-audio-ion {
		compatible = "qcom,msm-audio-ion";
	};

	pcm0: qcom,msm-pcm {
		compatible = "qcom,msm-pcm-dsp";
		qcom,msm-pcm-dsp-id = <0>;
	};

	pcm1: qcom,msm-pcm-low-latency {
		compatible = "qcom,msm-pcm-dsp";
		qcom,msm-pcm-dsp-id = <1>;
		qcom,msm-pcm-low-latency;
		qcom,latency-level = "regular";
	};

	pcm2: qcom,msm-ultra-low-latency {
		compatible = "qcom,msm-pcm-dsp";
		qcom,msm-pcm-dsp-id = <2>;
		qcom,msm-pcm-low-latency;
		qcom,latency-level = "ultra";
	};

	routing: qcom,msm-pcm-routing {
		compatible = "qcom,msm-pcm-routing";
	};

	compr: qcom,msm-compr-dsp {
		compatible = "qcom,msm-compr-dsp";
	};

	compress: qcom,msm-compress-dsp {
		compatible = "qcom,msm-compress-dsp";
	};

	voip: qcom,msm-voip-dsp {
		compatible = "qcom,msm-voip-dsp";
	};

	voice: qcom,msm-pcm-voice {
		compatible = "qcom,msm-pcm-voice";
	};

	stub_codec: qcom,msm-stub-codec {
		compatible = "qcom,msm-stub-codec";
	};

	qcom,msm-dai-fe {
		compatible = "qcom,msm-dai-fe";
	};

	afe: qcom,msm-pcm-afe {
		compatible = "qcom,msm-pcm-afe";
	};

	dai_hdmi: qcom,msm-dai-q6-hdmi {
		compatible = "qcom,msm-dai-q6-hdmi";
		qcom,msm-dai-q6-dev-id = <8>;
	};

	lsm: qcom,msm-lsm-client {
		compatible = "qcom,msm-lsm-client";
	};

	loopback: qcom,msm-pcm-loopback {
		compatible = "qcom,msm-pcm-loopback";
	};

	cpe: qcom,msm-cpe-lsm {
		compatible = "qcom,msm-cpe-lsm";
	};

	qcom,msm-dai-q6 {
		compatible = "qcom,msm-dai-q6";
		sb_0_rx: qcom,msm-dai-q6-sb-0-rx {
			compatible = "qcom,msm-dai-q6-dev";
			qcom,msm-dai-q6-dev-id = <16384>;
		};

		sb_0_tx: qcom,msm-dai-q6-sb-0-tx {
			compatible = "qcom,msm-dai-q6-dev";
			qcom,msm-dai-q6-dev-id = <16385>;
		};

		sb_1_rx: qcom,msm-dai-q6-sb-1-rx {
			compatible = "qcom,msm-dai-q6-dev";
			qcom,msm-dai-q6-dev-id = <16386>;
		};

		sb_1_tx: qcom,msm-dai-q6-sb-1-tx {
			compatible = "qcom,msm-dai-q6-dev";
			qcom,msm-dai-q6-dev-id = <16387>;
		};

		sb_2_rx: qcom,msm-dai-q6-sb-2-rx {
			compatible = "qcom,msm-dai-q6-dev";
			qcom,msm-dai-q6-dev-id = <16388>;
		};

		sb_2_tx: qcom,msm-dai-q6-sb-2-tx {
			compatible = "qcom,msm-dai-q6-dev";
			qcom,msm-dai-q6-dev-id = <16389>;
		};

		sb_3_rx: qcom,msm-dai-q6-sb-3-rx {
			compatible = "qcom,msm-dai-q6-dev";
			qcom,msm-dai-q6-dev-id = <16390>;
		};

		sb_3_tx: qcom,msm-dai-q6-sb-3-tx {
			compatible = "qcom,msm-dai-q6-dev";
			qcom,msm-dai-q6-dev-id = <16391>;
		};

		sb_4_rx: qcom,msm-dai-q6-sb-4-rx {
			compatible = "qcom,msm-dai-q6-dev";
			qcom,msm-dai-q6-dev-id = <16392>;
		};

		sb_4_tx: qcom,msm-dai-q6-sb-4-tx {
			compatible = "qcom,msm-dai-q6-dev";
			qcom,msm-dai-q6-dev-id = <16393>;
		};

		sb_5_tx: qcom,msm-dai-q6-sb-5-tx {
			compatible = "qcom,msm-dai-q6-dev";
			qcom,msm-dai-q6-dev-id = <16395>;
		};

		bt_sco_rx: qcom,msm-dai-q6-bt-sco-rx {
			compatible = "qcom,msm-dai-q6-dev";
			qcom,msm-dai-q6-dev-id = <12288>;
		};

		bt_sco_tx: qcom,msm-dai-q6-bt-sco-tx {
			compatible = "qcom,msm-dai-q6-dev";
			qcom,msm-dai-q6-dev-id = <12289>;
		};

		afe_pcm_rx: qcom,msm-dai-q6-be-afe-pcm-rx {
			compatible = "qcom,msm-dai-q6-dev";
			qcom,msm-dai-q6-dev-id = <224>;
		};

		afe_pcm_tx: qcom,msm-dai-q6-be-afe-pcm-tx {
			compatible = "qcom,msm-dai-q6-dev";
			qcom,msm-dai-q6-dev-id = <225>;
		};

		afe_proxy_rx: com,msm-dai-q6-afe-proxy-rx {
			compatible = "qcom,msm-dai-q6-dev";
			qcom,msm-dai-q6-dev-id = <241>;
		};

		afe_proxy_tx: qcom,msm-dai-q6-afe-proxy-tx {
			compatible = "qcom,msm-dai-q6-dev";
			qcom,msm-dai-q6-dev-id = <240>;
		};

		incall_record_rx: qcom,msm-dai-q6-incall-record-rx {
			compatible = "qcom,msm-dai-q6-dev";
			qcom,msm-dai-q6-dev-id = <32771>;
		};

		incall_record_tx: qcom,msm-dai-q6-incall-record-tx {
			compatible = "qcom,msm-dai-q6-dev";
			qcom,msm-dai-q6-dev-id = <32772>;
		};

		incall_music_rx: qcom,msm-dai-q6-incall-music-rx {
			compatible = "qcom,msm-dai-q6-dev";
			qcom,msm-dai-q6-dev-id = <32773>;
		};

		incall_music2_rx: qcom,msm-dai-q6-incall-music-2-rx {
			compatible = "qcom,msm-dai-q6-dev";
			qcom,msm-dai-q6-dev-id = <32770>;
		};
	};

	dai_pri_auxpcm: qcom,msm-pri-auxpcm {
		compatible = "qcom,msm-auxpcm-dev";
		qcom,msm-cpudai-auxpcm-mode = <0>, <0>;
		qcom,msm-cpudai-auxpcm-sync = <1>, <1>;
		qcom,msm-cpudai-auxpcm-frame = <5>, <4>;
		qcom,msm-cpudai-auxpcm-quant = <2>, <2>;
		qcom,msm-cpudai-auxpcm-num-slots = <1>, <1>;
		qcom,msm-cpudai-auxpcm-slot-mapping = <1>, <1>;
		qcom,msm-cpudai-auxpcm-data = <0>, <0>;
		qcom,msm-cpudai-auxpcm-pcm-clk-rate = <2048000>, <2048000>;
		qcom,msm-auxpcm-interface = "primary";
	};

	dai_sec_auxpcm: qcom,msm-sec-auxpcm {
		compatible = "qcom,msm-auxpcm-dev";
		qcom,msm-cpudai-auxpcm-mode = <0>, <0>;
		qcom,msm-cpudai-auxpcm-sync = <1>, <1>;
		qcom,msm-cpudai-auxpcm-frame = <5>, <4>;
		qcom,msm-cpudai-auxpcm-quant = <2>, <2>;
		qcom,msm-cpudai-auxpcm-num-slots = <1>, <1>;
		qcom,msm-cpudai-auxpcm-slot-mapping = <1>, <1>;
		qcom,msm-cpudai-auxpcm-data = <0>, <0>;
		qcom,msm-cpudai-auxpcm-pcm-clk-rate = <2048000>, <2048000>;
		qcom,msm-auxpcm-interface = "secondary";
	};

	qcom,msm-dai-mi2s {
		compatible = "qcom,msm-dai-mi2s";
		dai_mi2s: qcom,msm-dai-q6-mi2s-tert {
			compatible = "qcom,msm-dai-q6-mi2s";
			qcom,msm-dai-q6-mi2s-dev-id = <2>;
			qcom,msm-mi2s-rx-lines = <2>;
			qcom,msm-mi2s-tx-lines = <1>;
		};
	};

	hostless: qcom,msm-pcm-hostless {
		compatible = "qcom,msm-pcm-hostless";
	};

	qcom,msm-ssc-sensors {
		compatible = "qcom,msm-ssc-sensors";
		status = "ok";
	};

	cpu-pmu {
		compatible = "arm,armv8-pmuv3";
		qcom,irq-is-percpu;
		interrupts = <1 7 4>;
	};

	qcom,glink-smem-native-xprt-modem@86000000 {
		compatible = "qcom,glink-smem-native-xprt";
		reg = <0x86000000 0x200000>,
			<0x9820010 0x4>;
		reg-names = "smem", "irq-reg-base";
		qcom,irq-mask = <0x8000>;
		interrupts = <0 452 1>;
		label = "mpss";
	};

	qcom,glink-smem-native-xprt-adsp@86000000 {
		compatible = "qcom,glink-smem-native-xprt";
		reg = <0x86000000 0x200000>,
			<0x9820010 0x4>;
		reg-names = "smem", "irq-reg-base";
		qcom,irq-mask = <0x200>;
		interrupts = <0 157 1>;
		label = "lpass";
	};

	qcom,glink-smem-native-xprt-dsps@86000000 {
		compatible = "qcom,glink-smem-native-xprt";
		reg = <0x86000000 0x200000>,
			<0x9820010 0x4>;
		reg-names = "smem", "irq-reg-base";
		qcom,irq-mask = <0x8000000>;
		interrupts = <0 179 1>;
		label = "dsps";
	};

	qcom,glink-smem-native-xprt-rpm@68000 {
		compatible = "qcom,glink-rpm-native-xprt";
		reg = <0x68000 0x6000>,
			<0x7b4000 0x8>;
		reg-names = "msgram", "irq-reg-base";
		qcom,irq-mask = <0x2>;
		interrupts = <0 169 1>;
		label = "rpm";
	};

	glink_mpss: qcom,glink-ssr-modem {
		compatible = "qcom,glink_ssr";
		label = "modem";
		qcom,edge = "mpss";
		qcom,notify-edges = <&glink_lpass>, <&glink_dsps>, <&glink_rpm>;
		qcom,xprt = "smem";
	};

	glink_lpass: qcom,glink-ssr-adsp {
		compatible = "qcom,glink_ssr";
		label = "adsp";
		qcom,edge = "lpass";
		qcom,notify-edges = <&glink_mpss>, <&glink_dsps>, <&glink_rpm>;
		qcom,xprt = "smem";
	};

	glink_dsps: qcom,glink-ssr-dsps {
		compatible = "qcom,glink_ssr";
		label = "dsps";
		qcom,edge = "dsps";
		qcom,notify-edges = <&glink_mpss>, <&glink_lpass>, <&glink_rpm>;
		qcom,xprt = "smem";
	};

	glink_rpm: qcom,glink-ssr-rpm {
		compatible = "qcom,glink_ssr";
		label = "rpm";
		qcom,edge = "rpm";
		qcom,notify-edges = <&glink_lpass>, <&glink_mpss>, <&glink_dsps>;
		qcom,xprt = "smem";
	};
};

&gdsc_venus {
	status = "ok";
};

&gdsc_venus_core0 {
	status = "ok";
};

&gdsc_venus_core1 {
	status = "ok";
};

&gdsc_camss_top {
	status = "ok";
};

&gdsc_vfe0 {
	parent-supply = <&gdsc_camss_top>;
	status = "ok";
};

&gdsc_vfe1 {
	parent-supply = <&gdsc_camss_top>;
	status = "ok";
};

&gdsc_jpeg {
	parent-supply = <&gdsc_camss_top>;
	status = "ok";
};

&gdsc_cpp {
	parent-supply = <&gdsc_camss_top>;
	status = "ok";
};

&gdsc_fd {
	parent-supply = <&gdsc_camss_top>;
	status = "ok";
};

&gdsc_mdss {
	status = "ok";
};

&gdsc_pcie_0 {
	status = "ok";
};

&gdsc_pcie_1 {
	status = "ok";
};

&gdsc_pcie_2 {
	status = "ok";
};

&gdsc_usb30 {
	status = "ok";
};

&gdsc_ufs {
	status = "ok";
};

&gdsc_gpu {
	status = "ok";
};

&gdsc_gpu_gx {
	parent-supply = <&pmi8994_s2_corner>;
	status = "ok";
};

&gdsc_hlos1_vote_aggre0_noc {
	status = "ok";
};

&gdsc_hlos1_vote_lpass_adsp {
	status = "ok";
};

&gdsc_hlos1_vote_lpass_core {
	status = "ok";
};

&gdsc_hlos2_vote_aggre0_noc {
	status = "ok";
};

&gdsc_hlos2_vote_lpass_adsp {
	status = "ok";
};

&gdsc_hlos2_vote_lpass_core {
	status = "ok";
};

&gdsc_aggre0_noc {
	status = "ok";
};

&gdsc_mmagic_bimc {
	status = "ok";
};

&gdsc_mmagic_video {
	parent-supply = <&gdsc_mmagic_bimc>;
	status = "ok";
};

&gdsc_mmagic_mdss {
	parent-supply = <&gdsc_mmagic_bimc>;
	status = "ok";
};

&gdsc_mmagic_camss {
	parent-supply = <&gdsc_mmagic_bimc>;
	status = "ok";
};

&msm_vidc {
	qcom,use-non-secure-pil;
	qcom,fw-bias = <0x8cb00000>;
};

/include/ "msm-pm8994-rpm-regulator.dtsi"
/include/ "msm-pm8994.dtsi"
/include/ "msm-pmi8994.dtsi"
/include/ "msmthulium-regulator.dtsi"
#include "msmthulium-camera.dtsi"
#include "msmthulium-gpu.dtsi"
